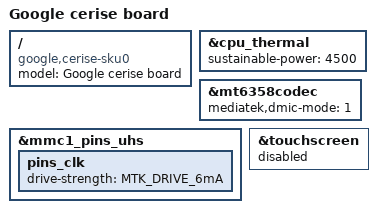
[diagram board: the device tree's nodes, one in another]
// SPDX-License-Identifier: (GPL-2.0 OR MIT)
/*
 * Copyright 2020 Google LLC
 */

/dts-v1/;
#include "mt8183-kukui-jacuzzi.dtsi"
#include "mt8183-kukui-audio-da7219-rt1015p.dtsi"

/ {
	model = "Google cerise board";
	compatible = "google,cerise-sku0", "google,cerise", "mediatek,mt8183";
};

&cpu_thermal {
	sustainable-power = <4500>; /* milliwatts */
};

&mt6358codec {
	mediatek,dmic-mode = <1>; /* one-wire */
};

&mmc1_pins_uhs {
	pins_clk {
		drive-strength = <MTK_DRIVE_6mA>;
	};
};

&touchscreen {
	status = "disabled";
};
